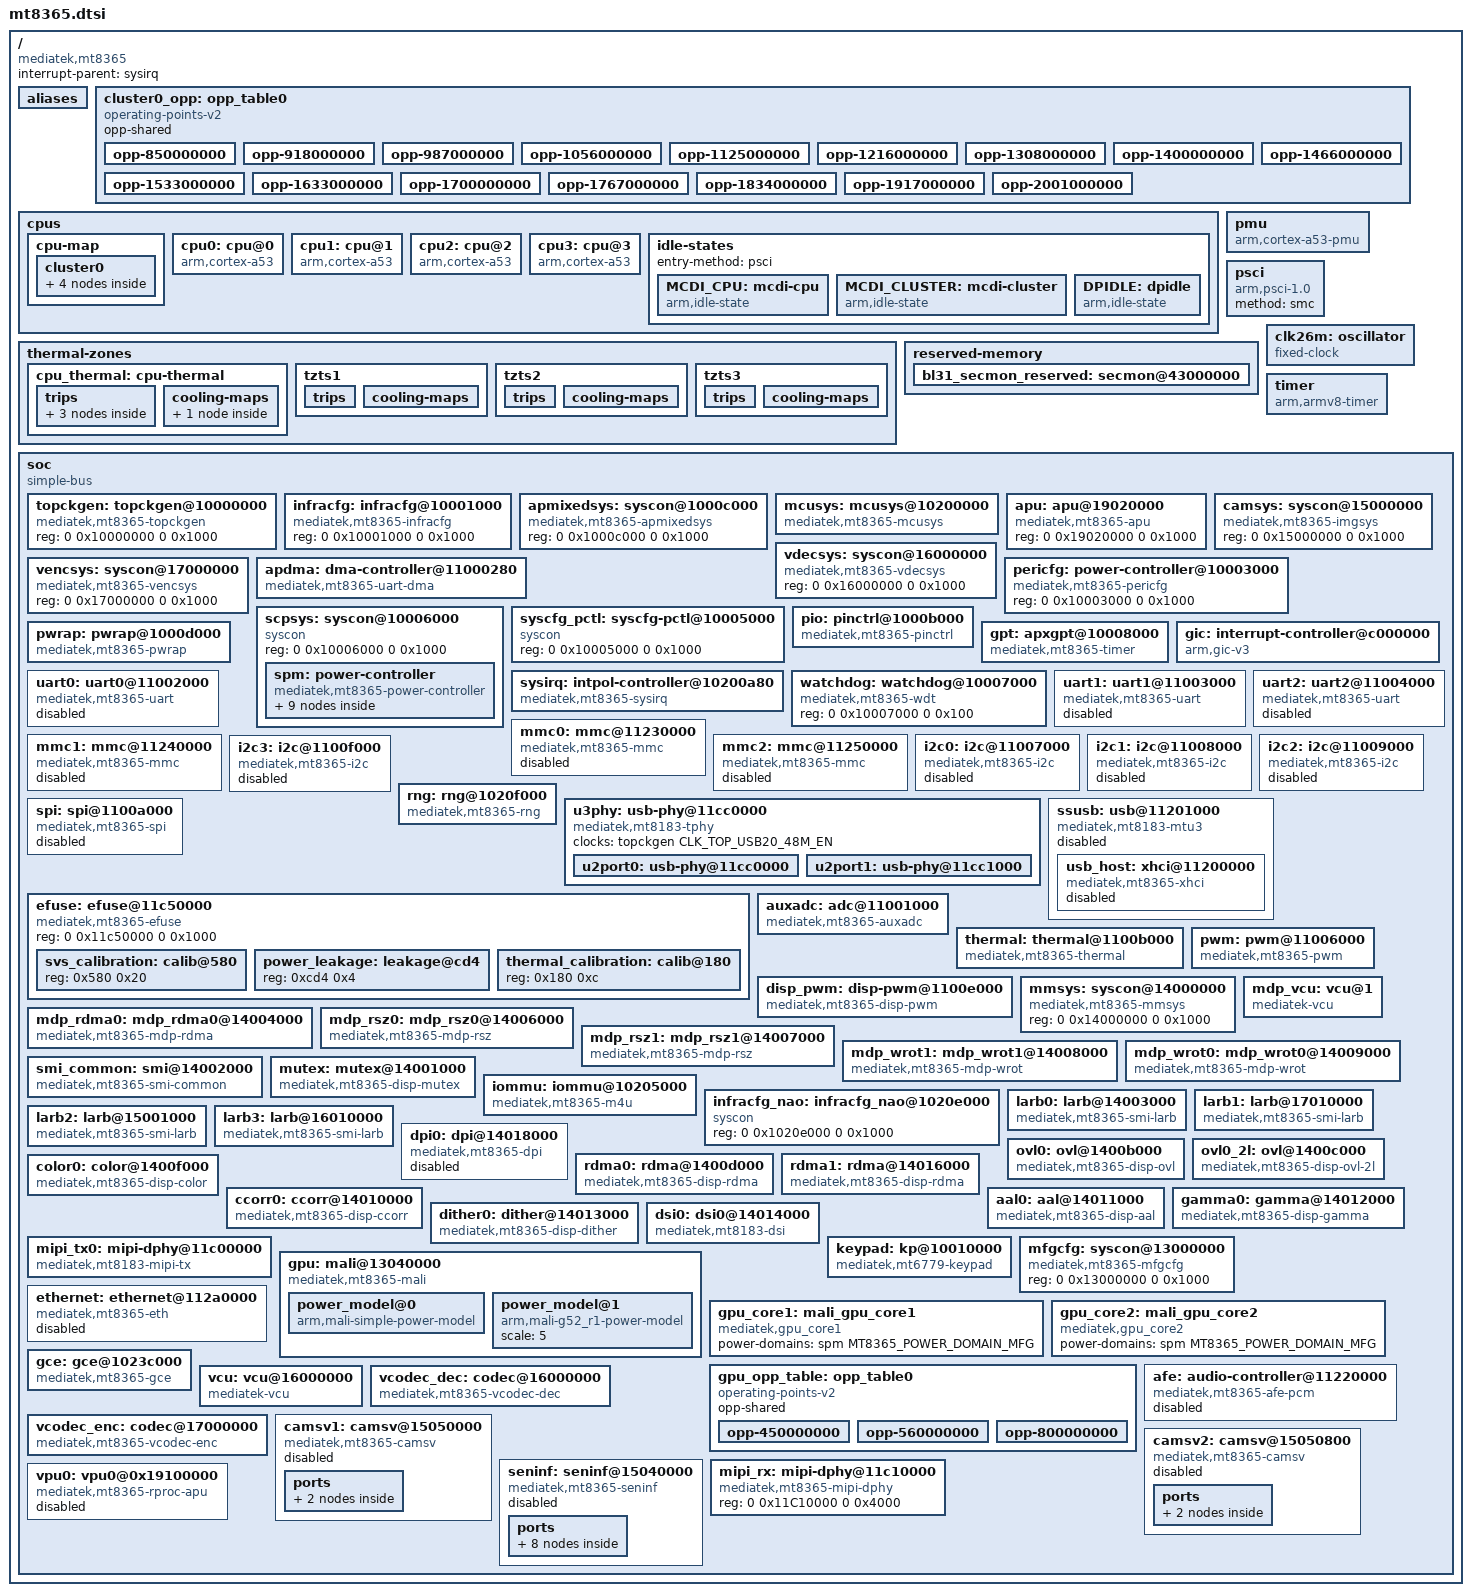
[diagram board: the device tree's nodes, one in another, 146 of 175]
// SPDX-License-Identifier: (GPL-2.0 OR MIT)
/*
 * Copyright (c) 2018 MediaTek Inc.
 */

#include <dt-bindings/clock/mt8365-clk.h>
#include <dt-bindings/interrupt-controller/arm-gic.h>
#include <dt-bindings/interrupt-controller/irq.h>
#include <dt-bindings/phy/phy.h>
#include <dt-bindings/gce/mt8365-gce.h>
#include <dt-bindings/power/mt8365-power.h>
#include <dt-bindings/memory/mt8365-larb-port.h>
#include <dt-bindings/thermal/thermal.h>

/ {
	compatible = "mediatek,mt8365";
	interrupt-parent = <&sysirq>;
	#address-cells = <2>;
	#size-cells = <2>;

	aliases {
		ovl0 = &ovl0;
		rdma0 = &rdma0;
		rdma1 = &rdma1;
		color0 = &color0;
		ccorr0 = &ccorr0;
		aal0 = &aal0;
		gamma0 = &gamma0;
		dither0 = &dither0;
		dsi0 = &dsi0;
		dpi0 = &dpi0;
	};

	cluster0_opp: opp_table0 {
		compatible = "operating-points-v2";
		opp-shared;
		opp-850000000 {
			opp-hz = /bits/ 64 <850000000>;
			opp-microvolt = <650000>;
		};
		opp-918000000 {
			opp-hz = /bits/ 64 <918000000>;
			opp-microvolt = <668750>;
		};
		opp-987000000 {
			opp-hz = /bits/ 64 <987000000>;
			opp-microvolt = <687500>;
		};
		opp-1056000000 {
			opp-hz = /bits/ 64 <1056000000>;
			opp-microvolt = <706250>;
		};
		opp-1125000000 {
			opp-hz = /bits/ 64 <1125000000>;
			opp-microvolt = <725000>;
		};
		opp-1216000000 {
			opp-hz = /bits/ 64 <1216000000>;
			opp-microvolt = <750000>;
		};
		opp-1308000000 {
			opp-hz = /bits/ 64 <1308000000>;
			opp-microvolt = <775000>;
		};
		opp-1400000000 {
			opp-hz = /bits/ 64 <1400000000>;
			opp-microvolt = <800000>;
		};
		opp-1466000000 {
			opp-hz = /bits/ 64 <1466000000>;
			opp-microvolt = <825000>;
		};
		opp-1533000000 {
			opp-hz = /bits/ 64 <1533000000>;
			opp-microvolt = <850000>;
		};
		opp-1633000000 {
			opp-hz = /bits/ 64 <1633000000>;
			opp-microvolt = <887500>;
		};
		opp-1700000000 {
			opp-hz = /bits/ 64 <1700000000>;
			opp-microvolt = <912500>;
		};
		opp-1767000000 {
			opp-hz = /bits/ 64 <1767000000>;
			opp-microvolt = <937500>;
		};
		opp-1834000000 {
			opp-hz = /bits/ 64 <1834000000>;
			opp-microvolt = <962500>;
		};
		opp-1917000000 {
			opp-hz = /bits/ 64 <1917000000>;
			opp-microvolt = <993750>;
		};
		opp-2001000000 {
			opp-hz = /bits/ 64 <2001000000>;
			opp-microvolt = <1025000>;
		};
	};

	cpus: cpus {
		#address-cells = <1>;
		#size-cells = <0>;

		cpu-map {
			cluster0: cluster0 {
				core0 {
					cpu = <&cpu0>;
				};
				core1 {
					cpu = <&cpu1>;
				};
				core2 {
					cpu = <&cpu2>;
				};
				core3 {
					cpu = <&cpu3>;
				};
			};
		};

		cpu0: cpu@0 {
			device_type = "cpu";
			compatible = "arm,cortex-a53";
			reg = <0x0>;
			clock-frequency = <1600000000>;
			clocks = <&mcusys CLK_MCU_BUS_SEL>,
				 <&apmixedsys CLK_APMIXED_MAINPLL>;
			clock-names = "cpu", "intermediate";
			cpu-idle-states = <&MCDI_CPU &MCDI_CLUSTER &DPIDLE>;
			operating-points-v2 = <&cluster0_opp>;
			#cooling-cells = <2>;
			enable-method = "psci";
		};

		cpu1: cpu@1 {
			device_type = "cpu";
			compatible = "arm,cortex-a53";
			reg = <0x1>;
			clock-frequency = <1600000000>;
			clocks = <&mcusys CLK_MCU_BUS_SEL>,
				 <&apmixedsys CLK_APMIXED_MAINPLL>;
			clock-names = "cpu", "intermediate", "armpll";
			cpu-idle-states = <&MCDI_CPU &MCDI_CLUSTER &DPIDLE>;
			operating-points-v2 = <&cluster0_opp>;
			#cooling-cells = <2>;
			enable-method = "psci";
		};

		cpu2: cpu@2 {
			device_type = "cpu";
			compatible = "arm,cortex-a53";
			reg = <0x2>;
			clock-frequency = <1600000000>;
			clocks = <&mcusys CLK_MCU_BUS_SEL>,
				 <&apmixedsys CLK_APMIXED_MAINPLL>;
			clock-names = "cpu", "intermediate", "armpll";
			cpu-idle-states = <&MCDI_CPU &MCDI_CLUSTER &DPIDLE>;
			operating-points-v2 = <&cluster0_opp>;
			#cooling-cells = <2>;
			enable-method = "psci";
		};

		cpu3: cpu@3 {
			device_type = "cpu";
			compatible = "arm,cortex-a53";
			reg = <0x3>;
			clock-frequency = <1600000000>;
			clocks = <&mcusys CLK_MCU_BUS_SEL>,
				 <&apmixedsys CLK_APMIXED_MAINPLL>;
			clock-names = "cpu", "intermediate", "armpll";
			cpu-idle-states = <&MCDI_CPU &MCDI_CLUSTER &DPIDLE>;
			operating-points-v2 = <&cluster0_opp>;
			#cooling-cells = <2>;
			enable-method = "psci";
		};

		idle-states {
			entry-method = "psci";

			MCDI_CPU: mcdi-cpu {
				compatible = "arm,idle-state";
				local-timer-stop;
				arm,psci-suspend-param = <0x00010001>;
				entry-latency-us = <300>;
				exit-latency-us = <200>;
				min-residency-us = <1000>;
			};

			MCDI_CLUSTER: mcdi-cluster {
				compatible = "arm,idle-state";
				local-timer-stop;
				arm,psci-suspend-param = <0x01010001>;
				entry-latency-us = <350>;
				exit-latency-us = <250>;
				min-residency-us = <1200>;
			};

			DPIDLE: dpidle {
				compatible = "arm,idle-state";
				local-timer-stop;
				arm,psci-suspend-param = <0x01010004>;
				entry-latency-us = <300>;
				exit-latency-us = <800>;
				min-residency-us = <3300>;
			};
		};
	};

	pmu {
		compatible = "arm,cortex-a53-pmu";
		interrupt-parent = <&gic>;
		interrupts = <GIC_PPI 7 IRQ_TYPE_LEVEL_LOW>;
	};

	thermal-zones {
		cpu_thermal: cpu-thermal {
			polling-delay-passive = <1000>; /* milliseconds */
			polling-delay = <1000>; /* milliseconds */
			thermal-sensors = <&thermal 0>;

			trips {
				threshold: trip-point0 {
					temperature = <95000>;
					hysteresis = <2000>;
					type = "passive";
				};

				target: trip-point1 {
					temperature = <105000>;
					hysteresis = <2000>;
					type = "passive";
				};

				cpu_crit: cpu_crit0 {
					temperature = <117000>;
					hysteresis = <2000>;
					type = "critical";
				};
			};

			cooling-maps {
				map0 {
					trip = <&target>;
					cooling-device =
						<&cpu0
						 THERMAL_NO_LIMIT
						 THERMAL_NO_LIMIT>,
						<&cpu1
						 THERMAL_NO_LIMIT
						 THERMAL_NO_LIMIT>,
						<&cpu2
						 THERMAL_NO_LIMIT
						 THERMAL_NO_LIMIT>,
						<&cpu3
						 THERMAL_NO_LIMIT
						 THERMAL_NO_LIMIT>;
					contribution = <100>;
				};
			};
		};

		tzts1: tzts1 {
			polling-delay-passive = <0>;
			polling-delay = <0>;
			thermal-sensors = <&thermal 1>;
			trips {};
			cooling-maps {};
		};

		tzts2: tzts2 {
			polling-delay-passive = <0>;
			polling-delay = <0>;
			thermal-sensors = <&thermal 2>;
			trips {};
			cooling-maps {};
		};

		tzts3: tzts3 {
			polling-delay-passive = <0>;
			polling-delay = <0>;
			thermal-sensors = <&thermal 3>;
			trips {};
			cooling-maps {};
		};
	};

	psci {
		compatible = "arm,psci-1.0";
		method = "smc";
	};

	reserved-memory {
		#address-cells = <2>;
		#size-cells = <2>;
		ranges;

		/* 192 KiB reserved for ARM Trusted Firmware (BL31) */
		bl31_secmon_reserved: secmon@43000000 {
			no-map;
			reg = <0 0x43000000 0 0x30000>;
		};
	};

	clk26m: oscillator {
		compatible = "fixed-clock";
		#clock-cells = <0>;
		clock-frequency = <26000000>;
		clock-output-names = "clk26m";
	};

	timer {
		compatible = "arm,armv8-timer";
		interrupt-parent = <&gic>;
		interrupts = <GIC_PPI 13 IRQ_TYPE_LEVEL_LOW 0>,
			     <GIC_PPI 14 IRQ_TYPE_LEVEL_LOW 0>,
			     <GIC_PPI 11 IRQ_TYPE_LEVEL_LOW 0>,
			     <GIC_PPI 10 IRQ_TYPE_LEVEL_LOW 0>;
	};

	soc {
		#address-cells = <2>;
		#size-cells = <2>;
		compatible = "simple-bus";
		ranges;

		topckgen: topckgen@10000000 {
			compatible = "mediatek,mt8365-topckgen", "syscon";
			reg = <0 0x10000000 0 0x1000>;
			#clock-cells = <1>;
		};

		infracfg: infracfg@10001000 {
			compatible = "mediatek,mt8365-infracfg", "syscon";
			reg = <0 0x10001000 0 0x1000>;
			#clock-cells = <1>;
		};

		apmixedsys: syscon@1000c000 {
			compatible = "mediatek,mt8365-apmixedsys", "syscon";
			reg = <0 0x1000c000 0 0x1000>;
			#clock-cells = <1>;
		};

		mcusys: mcusys@10200000 {
			compatible = "mediatek,mt8365-mcusys",
				     "mediatek,mt8365-mcucfg", "syscon";
			reg = <0 0x10200000 0 0x2000>;
			interrupts = <GIC_SPI 0 IRQ_TYPE_LEVEL_HIGH>;
			#clock-cells = <1>;
		};

		apu: apu@19020000 {
			compatible = "mediatek,mt8365-apu", "syscon";
			reg = <0 0x19020000 0 0x1000>;
			#clock-cells = <1>;
		};

		camsys: syscon@15000000 {
			compatible = "mediatek,mt8365-imgsys", "syscon";
			reg = <0 0x15000000 0 0x1000>;
			#clock-cells = <1>;
		};

		vdecsys: syscon@16000000 {
			compatible = "mediatek,mt8365-vdecsys", "syscon";
			reg = <0 0x16000000 0 0x1000>;
			#clock-cells = <1>;
		};

		vencsys: syscon@17000000 {
			compatible = "mediatek,mt8365-vencsys", "syscon";
			reg = <0 0x17000000 0 0x1000>;
			#clock-cells = <1>;
		};

		apdma: dma-controller@11000280 {
			compatible = "mediatek,mt8365-uart-dma",
				     "mediatek,mt6577-uart-dma";
			reg = <0 0x11000280 0 0x80>,
			      <0 0x11000300 0 0x80>,
			      <0 0x11000380 0 0x80>,
			      <0 0x11000400 0 0x80>,
			      <0 0x11000580 0 0x80>,
			      <0 0x11000600 0 0x80>;
			interrupts = <GIC_SPI 45 IRQ_TYPE_LEVEL_LOW>,
				     <GIC_SPI 46 IRQ_TYPE_LEVEL_LOW>,
				     <GIC_SPI 47 IRQ_TYPE_LEVEL_LOW>,
				     <GIC_SPI 48 IRQ_TYPE_LEVEL_LOW>,
				     <GIC_SPI 51 IRQ_TYPE_LEVEL_LOW>,
				     <GIC_SPI 52 IRQ_TYPE_LEVEL_LOW>;
			dma-requests = <6>;
			clocks = <&infracfg CLK_IFR_AP_DMA>;
			clock-names = "apdma";
			#dma-cells = <1>;
		};

		pericfg: power-controller@10003000 {
			compatible = "mediatek,mt8365-pericfg", "syscon";
			reg = <0 0x10003000 0 0x1000>;
			#clock-cells = <1>;
			#reset-cells = <1>;
		};

		scpsys: syscon@10006000 {
			compatible = "syscon", "simple-mfd";
			reg = <0 0x10006000 0 0x1000>;
			#power-domain-cells = <1>;

			/* System Power Manager */
			spm: power-controller {
				compatible = "mediatek,mt8365-power-controller";
				#address-cells = <1>;
				#size-cells = <0>;
				#power-domain-cells = <1>;

				/* power domains of the SoC */
				power-domain@MT8365_POWER_DOMAIN_MM {
					reg = <MT8365_POWER_DOMAIN_MM>;
					clocks = <&topckgen CLK_TOP_MM_SEL>,
						 <&mmsys CLK_MM_MM_SMI_COMMON>,
						 <&mmsys CLK_MM_MM_SMI_COMM0>,
						 <&mmsys CLK_MM_MM_SMI_COMM1>,
						 <&mmsys CLK_MM_MM_SMI_LARB0>;
					clock-names = "mm", "mm-0", "mm-1",
						      "mm-2", "mm-3";
					#power-domain-cells = <0>;
					mediatek,infracfg = <&infracfg>;
					mediatek,infracfg_nao = <&infracfg_nao>;
					#address-cells = <1>;
					#size-cells = <0>;

					power-domain@MT8365_POWER_DOMAIN_CAM {
						reg = <MT8365_POWER_DOMAIN_CAM>;
						clocks = <&camsys CLK_CAM_LARB2>,
							 <&camsys CLK_CAM_SENIF>,
							 <&camsys CLK_CAMSV0>,
							 <&camsys CLK_CAMSV1>,
							 <&camsys CLK_CAM_FDVT>,
							 <&camsys CLK_CAM_WPE>;
						clock-names = "cam-0", "cam-1",
							      "cam-2", "cam-3",
							      "cam-4", "cam-5";
						#power-domain-cells = <0>;
						mediatek,infracfg = <&infracfg>;
						mediatek,smi = <&smi_common>;
					};

					power-domain@MT8365_POWER_DOMAIN_VDEC {
						reg = <MT8365_POWER_DOMAIN_VDEC>;
						#power-domain-cells = <0>;
						mediatek,smi = <&smi_common>;
					};

					power-domain@MT8365_POWER_DOMAIN_VENC {
						reg = <MT8365_POWER_DOMAIN_VENC>;
						#power-domain-cells = <0>;
						mediatek,smi = <&smi_common>;
					};

					power-domain@MT8365_POWER_DOMAIN_APU {
						reg = <MT8365_POWER_DOMAIN_APU>;
						clocks = <&infracfg CLK_IFR_APU_AXI>,
							 <&apu CLK_APU_IPU_CK>,
							 <&apu CLK_APU_AXI>,
							 <&apu CLK_APU_JTAG>,
							 <&apu CLK_APU_IF_CK>,
							 <&apu CLK_APU_EDMA>,
							 <&apu CLK_APU_AHB>;
						clock-names = "apu", "apu-0",
							      "apu-1", "apu-2",
							      "apu-3", "apu-4",
							      "apu-5";
						#power-domain-cells = <0>;
						mediatek,infracfg = <&infracfg>;
						mediatek,smi = <&smi_common>;
					};
				};

				power-domain@MT8365_POWER_DOMAIN_CONN {
					reg = <MT8365_POWER_DOMAIN_CONN>;
					clocks = <&topckgen CLK_TOP_CONN_32K>,
						 <&topckgen CLK_TOP_CONN_26M>;
					clock-names = "conn", "conn1";
					#power-domain-cells = <0>;
					mediatek,infracfg = <&infracfg>;
				};

				power-domain@MT8365_POWER_DOMAIN_MFG {
					reg = <MT8365_POWER_DOMAIN_MFG>;
					clocks = <&topckgen CLK_TOP_MFG_SEL>;
					clock-names = "mfg";
					#power-domain-cells = <0>;
					mediatek,infracfg = <&infracfg>;
				};

				power-domain@MT8365_POWER_DOMAIN_AUDIO {
					reg = <MT8365_POWER_DOMAIN_AUDIO>;
					clocks = <&topckgen CLK_TOP_AUD_INTBUS_SEL>,
						 <&infracfg CLK_IFR_AUDIO>,
						 <&infracfg CLK_IFR_AUD_26M_BK>;
					clock-names = "audio", "audio1", "audio2";
					#power-domain-cells = <0>;
					mediatek,infracfg = <&infracfg>;
				};

				power-domain@MT8365_POWER_DOMAIN_DSP {
					reg = <MT8365_POWER_DOMAIN_DSP>;
					clocks = <&topckgen CLK_TOP_DSP_SEL>,
						 <&topckgen CLK_TOP_DSP_26M>;
					clock-names = "dsp", "dsp1";
					#power-domain-cells = <0>;
					mediatek,infracfg = <&infracfg>;
				};
			};
		};

		syscfg_pctl: syscfg-pctl@10005000 {
			compatible = "syscon";
			reg = <0 0x10005000 0 0x1000>;
		};

		pio: pinctrl@1000b000 {
			compatible = "mediatek,mt8365-pinctrl";
			reg = <0 0x1000b000 0 0x1000>;
			mediatek,pctl-regmap = <&syscfg_pctl>;
			pins-are-numbered;
			gpio-controller;
			#gpio-cells = <2>;
			interrupt-controller;
			#interrupt-cells = <2>;
			interrupts = <GIC_SPI 115 IRQ_TYPE_LEVEL_HIGH>;
		};

		pwrap: pwrap@1000d000 {
			compatible = "mediatek,mt8365-pwrap";
			reg = <0 0x1000d000 0 0x1000>;
			reg-names = "pwrap";
			interrupts = <GIC_SPI 123 IRQ_TYPE_LEVEL_HIGH>;
			clocks = <&infracfg CLK_IFR_PWRAP_SPI>,
				 <&infracfg CLK_IFR_PMIC_AP>,
				 <&infracfg CLK_IFR_PWRAP_SYS>,
				 <&infracfg CLK_IFR_PWRAP_TMR>;
			clock-names = "spi", "wrap", "wrap_sys", "wrap_tmr";
		};

		gpt: apxgpt@10008000 {
			compatible = "mediatek,mt8365-timer",
				     "mediatek,mt6577-timer";
			reg = <0 0x10008000 0 0x1000>;
			interrupts = <GIC_SPI 114 IRQ_TYPE_LEVEL_LOW>;
			clocks = <&topckgen CLK_TOP_SYS_26M_D2>;
			clock-names = "clk13m";
		};

		gic: interrupt-controller@c000000 {
			compatible = "arm,gic-v3";
			#interrupt-cells = <3>;
			interrupt-parent = <&gic>;
			interrupt-controller;
			reg = <0 0xc000000 0 0x80000>,
			      <0 0xc080000 0 0x80000>;

			interrupts = <GIC_PPI 9
				(GIC_CPU_MASK_SIMPLE(4) | IRQ_TYPE_LEVEL_HIGH)>;
		};

		sysirq: intpol-controller@10200a80 {
			compatible = "mediatek,mt8365-sysirq",
				     "mediatek,mt6577-sysirq";
			interrupt-controller;
			#interrupt-cells = <3>;
			interrupt-parent = <&gic>;
			reg = <0 0x10200a80 0 0x20>;
		};

		watchdog: watchdog@10007000 {
			compatible = "mediatek,mt8365-wdt",
				     "mediatek,mt6589-wdt";
			reg = <0 0x10007000 0 0x100>;
			#reset-cells = <1>;
		};

		uart0: uart0@11002000 {
			compatible = "mediatek,mt8365-uart",
				     "mediatek,mt6577-uart";
			reg = <0 0x11002000 0 0x1000>;
			interrupts = <GIC_SPI 35 IRQ_TYPE_LEVEL_LOW>;
			clocks = <&clk26m>, <&infracfg CLK_IFR_UART0>;
			clock-names = "baud", "bus";
			dmas = <&apdma 0
				&apdma 1>;
			dma-names = "tx", "rx";
			status = "disabled";
		};

		uart1: uart1@11003000 {
			compatible = "mediatek,mt8365-uart",
				     "mediatek,mt6577-uart";
			reg = <0 0x11003000 0 0x1000>;
			interrupts = <GIC_SPI 36 IRQ_TYPE_LEVEL_LOW>;
			clocks = <&clk26m>, <&infracfg CLK_IFR_UART1>;
			clock-names = "baud", "bus";
			dmas = <&apdma 2
				&apdma 3>;
			dma-names = "tx", "rx";
			status = "disabled";
		};

		uart2: uart2@11004000 {
			compatible = "mediatek,mt8365-uart",
				     "mediatek,mt6577-uart";
			reg = <0 0x11004000 0 0x1000>;
			interrupts = <GIC_SPI 37 IRQ_TYPE_LEVEL_LOW>;
			clocks = <&clk26m>, <&infracfg CLK_IFR_UART2>;
			clock-names = "baud", "bus";
			dmas = <&apdma 4
				&apdma 5>;
			dma-names = "tx", "rx";
			status = "disabled";
		};

		mmc0: mmc@11230000 {
			compatible = "mediatek,mt8365-mmc",
				     "mediatek,mt8183-mmc";
			reg = <0 0x11230000 0 0x1000>,
			      <0 0x11cd0000 0 0x1000>;
			interrupts = <GIC_SPI 23 IRQ_TYPE_LEVEL_LOW>;
			clocks = <&topckgen CLK_TOP_MSDC50_0_SEL>,
				 <&infracfg CLK_IFR_MSDC0_HCLK>,
				 <&infracfg CLK_IFR_MSDC0_SRC>;
			clock-names = "source", "hclk", "source_cg";
			status = "disabled";
		};

		mmc1: mmc@11240000 {
			compatible = "mediatek,mt8365-mmc",
				     "mediatek,mt8183-mmc";
			reg = <0 0x11240000 0 0x1000>,
			      <0 0x11c90000 0 0x1000>;
			interrupts = <GIC_SPI 24 IRQ_TYPE_LEVEL_LOW>;
			clocks = <&topckgen CLK_TOP_MSDC30_1_SEL>,
				 <&infracfg CLK_IFR_MSDC1_HCLK>,
				 <&infracfg CLK_IFR_MSDC1_SRC>;
			clock-names = "source", "hclk", "source_cg";
			status = "disabled";
		};

		mmc2: mmc@11250000 {
			compatible = "mediatek,mt8365-mmc",
				     "mediatek,mt8183-mmc";
			reg = <0 0x11250000 0 0x1000>,
			      <0 0x11c60000 0 0x1000>;
			interrupts = <GIC_SPI 68 IRQ_TYPE_LEVEL_LOW>;
			clocks = <&topckgen CLK_TOP_MSDC50_2_SEL>,
				 <&infracfg CLK_IFR_MSDC2_HCLK>,
				 <&infracfg CLK_IFR_MSDC2_SRC>,
				 <&infracfg CLK_IFR_MSDC2_BK>,
				 <&infracfg CLK_IFR_AP_MSDC0>;
			clock-names = "source", "hclk", "source_cg",
				      "bus_clk", "sys_cg";
			mediatek,disable-single-burst;
			status = "disabled";
		};

		i2c0: i2c@11007000 {
			compatible = "mediatek,mt8365-i2c";
			reg = <0 0x11007000 0 0xa0>,
			      <0 0x11000080 0 0x80>;
			interrupts = <GIC_SPI 28 IRQ_TYPE_LEVEL_LOW>;
			clock-div = <1>;
			clocks = <&infracfg CLK_IFR_I2C0_AXI>,
				 <&infracfg CLK_IFR_AP_DMA>;
			clock-names = "main", "dma";
			#address-cells = <1>;
			#size-cells = <0>;
			status = "disabled";
		};

		i2c1: i2c@11008000 {
			compatible = "mediatek,mt8365-i2c";
			reg = <0 0x11008000 0 0xa0>,
			      <0 0x11000100 0 0x80>;
			interrupts = <GIC_SPI 29 IRQ_TYPE_LEVEL_LOW>;
			clock-div = <1>;
			clocks = <&infracfg CLK_IFR_I2C1_AXI>,
				 <&infracfg CLK_IFR_AP_DMA>;
			clock-names = "main", "dma";
			#address-cells = <1>;
			#size-cells = <0>;
			status = "disabled";
		};

		i2c2: i2c@11009000 {
			compatible = "mediatek,mt8365-i2c";
			reg = <0 0x11009000 0 0xa0>,
			      <0 0x11000180 0 0x80>;
			interrupts = <GIC_SPI 30 IRQ_TYPE_LEVEL_LOW>;
			clock-div = <1>;
			clocks = <&infracfg CLK_IFR_I2C2_AXI>,
				 <&infracfg CLK_IFR_AP_DMA>;
			clock-names = "main", "dma";
			#address-cells = <1>;
			#size-cells = <0>;
			status = "disabled";
		};

		i2c3: i2c@1100f000 {
			compatible = "mediatek,mt8365-i2c";
			reg = <0 0x1100f000 0 0xa0>,
			      <0 0x11000200 0 0x80>;
			interrupts = <GIC_SPI 31 IRQ_TYPE_LEVEL_LOW>;
			clock-div = <1>;
			clocks = <&infracfg CLK_IFR_I2C3_AXI>,
				 <&infracfg CLK_IFR_AP_DMA>;
			clock-names = "main", "dma";
			#address-cells = <1>;
			#size-cells = <0>;
			status = "disabled";
		};

		rng: rng@1020f000 {
			compatible = "mediatek,mt8365-rng",
				     "mediatek,mt7623-rng";
			reg = <0 0x1020f000 0 0x100>;
			clocks = <&infracfg CLK_IFR_TRNG>;
			clock-names = "rng";
		};

		u3phy: usb-phy@11cc0000 {
			compatible = "mediatek,mt8183-tphy",
				     "mediatek,generic-tphy-v2";
			clocks = <&topckgen CLK_TOP_USB20_48M_EN>;
			clock-names = "u3phya_ref";
			#address-cells = <2>;
			#phy-cells = <1>;
			#size-cells = <2>;
			ranges;
			status = "okay";

			u2port0: usb-phy@11cc0000 {
				reg = <0 0x11cc0000 0 0x400>;
				clocks = <&topckgen CLK_TOP_SSUSB_PHY_CK_EN>,
					 <&topckgen CLK_TOP_USB20_48M_EN>;
				clock-names = "ref", "da_ref";
				#phy-cells = <1>;
				status = "okay";
			};

			u2port1: usb-phy@11cc1000 {
				reg = <0 0x11cc1000 0 0x400>;
				clocks = <&topckgen CLK_TOP_SSUSB_PHY_CK_EN>,
					 <&topckgen CLK_TOP_USB20_48M_EN>;
				clock-names = "ref", "da_ref";
				#phy-cells = <1>;
				status = "okay";
			};
		};

		ssusb: usb@11201000 {
			compatible ="mediatek,mt8183-mtu3", "mediatek,mtu3";
			reg = <0 0x11201000 0 0x2e00>,
			      <0 0x11203e00 0 0x0100>;
			reg-names = "mac", "ippc";
			interrupts = <GIC_SPI 16 IRQ_TYPE_LEVEL_LOW>;
			phys = <&u2port0 PHY_TYPE_USB2>,
			       <&u2port1 PHY_TYPE_USB2>;
			clocks = <&topckgen CLK_TOP_SSUSB_TOP_CK_EN>,
				 <&infracfg CLK_IFR_SSUSB_REF>,
				 <&infracfg CLK_IFR_SSUSB_SYS>,
				 <&infracfg CLK_IFR_ICUSB>;
			clock-names = "sys_ck", "ref_ck", "mcu_ck",
				      "dma_ck";
			#address-cells = <2>;
			#size-cells = <2>;
			ranges;
			status = "disabled";
			wakeup-source;
			mediatek,syscon-wakeup = <&pericfg 0x400 0>;

			usb_host: xhci@11200000 {
				compatible = "mediatek,mt8365-xhci",
					     "mediatek,mtk-xhci";
				reg = <0 0x11200000 0 0x1000>;
				reg-names = "mac";
				interrupts = <GIC_SPI 67 IRQ_TYPE_LEVEL_LOW>;
				clocks = <&topckgen CLK_TOP_SSUSB_TOP_CK_EN>,
					 <&infracfg CLK_IFR_SSUSB_REF>,
					 <&infracfg CLK_IFR_SSUSB_SYS>,
					 <&infracfg CLK_IFR_ICUSB>,
					 <&infracfg CLK_IFR_SSUSB_XHCI>;
				clock-names = "sys_ck", "ref_ck", "mcu_ck",
					      "dma_ck", "xhci_ck";
				status = "disabled";
			};
		};

		spi: spi@1100a000 {
			compatible = "mediatek,mt8365-spi",
				     "mediatek,mt7622-spi";
			#address-cells = <1>;
			#size-cells = <0>;
			reg = <0 0x1100a000 0 0x100>;
			interrupts = <GIC_SPI 62 IRQ_TYPE_LEVEL_LOW>;
			clocks = <&topckgen CLK_TOP_UNIVPLL2_D4>,
				 <&topckgen CLK_TOP_SPI_SEL>,
				 <&infracfg CLK_IFR_SPI0>;
			clock-names = "parent-clk", "sel-clk", "spi-clk";
			status = "disabled";
		};

		efuse: efuse@11c50000 {
			compatible = "mediatek,mt8365-efuse", "mediatek,efuse";
			reg = <0 0x11c50000 0 0x1000>;
			#address-cells = <1>;
			#size-cells = <1>;

			svs_calibration: calib@580 {
				reg = <0x580 0x20>;
			};

			power_leakage: leakage@cd4 {
				reg = <0xcd4 0x4>;
			};

			thermal_calibration: calib@180 {
				reg = <0x180 0xc>;
			};
		};

		auxadc: adc@11001000 {
			compatible = "mediatek,mt8365-auxadc",
				     "mediatek,mt8173-auxadc";
			reg = <0 0x11001000 0 0x1000>;
			clocks = <&infracfg CLK_IFR_AUXADC>;
			clock-names = "main";
			#io-channel-cells = <1>;
		};

		thermal: thermal@1100b000 {
			compatible = "mediatek,mt8365-thermal";
			reg = <0 0x1100b000 0 0x1000>;
			interrupts = <GIC_SPI 22 IRQ_TYPE_LEVEL_LOW>;
			clocks = <&infracfg CLK_IFR_THERM>,
				 <&infracfg CLK_IFR_AUXADC>;
			clock-names = "therm", "auxadc";
			mediatek,auxadc = <&auxadc>;
			mediatek,apmixedsys = <&apmixedsys>;
			nvmem-cells = <&thermal_calibration>;
			nvmem-cell-names = "calibration-data";
			#thermal-sensor-cells = <1>;
		};

		pwm: pwm@11006000 {
			compatible = "mediatek,mt8365-pwm";
			reg = <0 0x11006000 0 0x1000>;
			#pwm-cells = <2>;
			interrupts = <GIC_SPI 76 IRQ_TYPE_LEVEL_LOW>;
			clocks = <&infracfg CLK_IFR_PWM_HCLK>,
				 <&infracfg CLK_IFR_PWM>,
				 <&infracfg CLK_IFR_PWM1>,
				 <&infracfg CLK_IFR_PWM2>,
				 <&infracfg CLK_IFR_PWM3>;
			clock-names = "top", "main", "pwm1", "pwm2", "pwm3";
		};

		disp_pwm: disp-pwm@1100e000 {
			compatible = "mediatek,mt8365-disp-pwm",
				     "mediatek,mt8183-disp-pwm";
			reg = <0 0x1100e000 0 0x1000>;
			#pwm-cells = <2>;
			clocks = <&topckgen CLK_TOP_DISP_PWM_SEL>,
				 <&infracfg CLK_IFR_DISP_PWM>;
			clock-names = "main", "mm";
			power-domains = <&spm MT8365_POWER_DOMAIN_MM>;
		};

		mmsys: syscon@14000000 {
			compatible = "mediatek,mt8365-mmsys", "syscon";
			reg = <0 0x14000000 0 0x1000>;
			#clock-cells = <1>;
		};

		mdp_vcu: vcu@1 {
			compatible = "mediatek-vcu",
				     "mediatek,mt8167-vcu";
			mediatek,vcuid = <1>;
			mediatek,vcuname = "vcu1";
			iommus = <&iommu M4U_PORT_HW_VDEC_MC_EXT>;
		};

		mdp_rdma0: mdp_rdma0@14004000 {
			compatible = "mediatek,mt8365-mdp-rdma",
						"mediatek,mt8167-mdp-rdma",
						"mediatek,mt8167-mdp";
			reg = <0 0x14004000 0 0x1000>;
			mediatek,mdp-id = <0>;
			clocks = <&mmsys CLK_MM_MM_MDP_RDMA0>,
				 <&mmsys CLK_MM_MM_MDP_RDMA0>;
			power-domains = <&spm MT8365_POWER_DOMAIN_MM>;
			iommus = <&iommu M4U_PORT_MDP_RDMA0>;
			mediatek,larb = <&larb0>;
			mediatek,vpu = <&mdp_vcu>;
			mediatek,gce = <&gce>;
			mboxes = <&gce 8 2 1>;
		};

		mdp_rsz0: mdp_rsz0@14006000 {
			compatible = "mediatek,mt8365-mdp-rsz",
						"mediatek,mt8167-mdp-rsz";
			mediatek,mdp-id = <0>;
			reg = <0 0x14006000 0 0x1000>;
			mediatek,gce-client-reg = <&gce SUBSYS_1400XXXX 0x6000 0x1000>;
			clocks = <&mmsys CLK_MM_MM_MDP_RSZ0>;
		};

		mdp_rsz1: mdp_rsz1@14007000 {
			compatible = "mediatek,mt8365-mdp-rsz",
						"mediatek,mt8167-mdp-rsz";
			mediatek,mdp-id = <1>;
			reg = <0 0x14007000 0 0x1000>;
			mediatek,gce-client-reg = <&gce SUBSYS_1400XXXX 0x7000 0x1000>;
			clocks = <&mmsys CLK_MM_MM_MDP_RSZ1>;
		};

		mdp_wrot1: mdp_wrot1@14008000 {
			compatible = "mediatek,mt8365-mdp-wrot",
						"mediatek,mt8167-mdp-wrot";
			mediatek,mdp-id = <0>;
			reg = <0 0x14008000 0 0x1000>;
			power-domains = <&spm MT8365_POWER_DOMAIN_MM>;
			mediatek,gce-client-reg = <&gce SUBSYS_1400XXXX 0x8000 0x1000>;
			clocks = <&mmsys CLK_MM_MM_MDP_WDMA0>;
			iommus = <&iommu M4U_PORT_MDP_WROT1>;
			mediatek,larb = <&larb0>;
		};

		mdp_wrot0: mdp_wrot0@14009000 {
			compatible = "mediatek,mt8365-mdp-wrot",
						"mediatek,mt8167-mdp-wrot";
			mediatek,mdp-id = <0>;
			reg = <0 0x14009000 0 0x1000>;
			power-domains = <&spm MT8365_POWER_DOMAIN_MM>;
			mediatek,gce-client-reg = <&gce SUBSYS_1400XXXX 0x9000 0x1000>;
			clocks = <&mmsys CLK_MM_MM_MDP_WROT0>;
			iommus = <&iommu M4U_PORT_MDP_WROT0>;
			mediatek,larb = <&larb0>;
		};

		smi_common: smi@14002000 {
			compatible = "mediatek,mt8365-smi-common", "syscon";
			reg = <0 0x14002000 0 0x1000>;
			clocks = <&mmsys CLK_MM_MM_SMI_COMMON>,
				 <&mmsys CLK_MM_MM_SMI_COMMON>,
				 <&mmsys CLK_MM_MM_SMI_COMM0>,
				 <&mmsys CLK_MM_MM_SMI_COMM1>;
			clock-names = "apb", "smi", "gals0", "gals1";
			mediatek,mmsys = <&mmsys>;
		};

		mutex: mutex@14001000 {
			compatible =  "mediatek,mt8365-disp-mutex";
			reg = <0 0x14001000 0 0x1000>;
			interrupts = <GIC_SPI 154 IRQ_TYPE_LEVEL_LOW>;
			power-domains = <&spm MT8365_POWER_DOMAIN_MM>;
		};

		iommu: iommu@10205000 {
			compatible = "mediatek,mt8365-m4u";
			reg = <0 0x10205000 0 0x1000>;
			interrupts = <GIC_SPI 102 IRQ_TYPE_LEVEL_LOW>;
			mediatek,larbs = <&larb0 &larb1 &larb2 &larb3>;
			#iommu-cells = <1>;
		};

		infracfg_nao: infracfg_nao@1020e000 {
			compatible = "syscon";
			reg = <0 0x1020e000 0 0x1000>;
		};

		larb0: larb@14003000 {
			compatible = "mediatek,mt8365-smi-larb",
				     "mediatek,mt8183-smi-larb";
			reg = <0 0x14003000 0 0x1000>;
			mediatek,smi = <&smi_common>;
			clocks = <&mmsys CLK_MM_MM_SMI_LARB0>,
				 <&mmsys CLK_MM_MM_SMI_LARB0>;
			clock-names = "apb", "smi";
			power-domains = <&spm MT8365_POWER_DOMAIN_MM>;
		};

		larb1: larb@17010000 {
			compatible = "mediatek,mt8365-smi-larb",
				     "mediatek,mt8183-smi-larb";
			reg = <0 0x17010000 0 0x1000>;
			mediatek,smi = <&smi_common>;
			clocks = <&vencsys CLK_VENC>, <&vencsys CLK_VENC>;
			clock-names = "apb", "smi";
			power-domains = <&spm MT8365_POWER_DOMAIN_VENC>;
		};

		larb2: larb@15001000 {
			compatible = "mediatek,mt8365-smi-larb",
				     "mediatek,mt8183-smi-larb";
			reg = <0 0x15001000 0 0x1000>;
			mediatek,smi = <&smi_common>;
			clocks = <&mmsys CLK_MM_MM_SMI_IMG>,
				 <&camsys CLK_CAM_LARB2>;
			clock-names = "apb", "smi";
			power-domains = <&spm MT8365_POWER_DOMAIN_CAM>;
		};

		larb3: larb@16010000 {
			compatible = "mediatek,mt8365-smi-larb",
				     "mediatek,mt8183-smi-larb";
			reg = <0 0x16010000 0 0x1000>;
			mediatek,smi = <&smi_common>;
			clocks = <&vdecsys CLK_VDEC_LARB1>,
				 <&vdecsys CLK_VDEC_LARB1>;
			clock-names = "apb", "smi";
			power-domains = <&spm MT8365_POWER_DOMAIN_VDEC>;
		};

		dpi0: dpi@14018000 {
			compatible = "mediatek,mt8365-dpi";
			reg = <0 0x14018000 0 0x1000>;
			interrupts = <GIC_SPI 197 IRQ_TYPE_LEVEL_LOW>;
			power-domains = <&spm MT8365_POWER_DOMAIN_MM>;
			clocks = <&mmsys CLK_MM_DPI0_DPI0>,
				 <&mmsys CLK_MM_MM_DPI0>,
				 <&apmixedsys CLK_APMIXED_LVDSPLL>,
				 <&topckgen CLK_TOP_DPI0_SEL>;
			clock-names = "dpi_sel", "engine", "pll", "pixel";
			assigned-clocks = <&topckgen CLK_TOP_DPI0_SEL>;
			assigned-clock-parents = <&topckgen CLK_TOP_LVDSPLL_D4>;
			status = "disabled";
		};

		ovl0: ovl@1400b000 {
			compatible = "mediatek,mt8365-disp-ovl",
				     "mediatek,mt8183-disp-ovl";
			reg = <0 0x1400b000 0 0x1000>;
			interrupts = <GIC_SPI 161 IRQ_TYPE_LEVEL_LOW>;
			power-domains = <&spm MT8365_POWER_DOMAIN_MM>;
			clocks = <&mmsys CLK_MM_MM_DISP_OVL0>;
			iommus = <&iommu M4U_PORT_DISP_OVL0>;
			mediatek,larb = <&larb0>;
		};

		ovl0_2l: ovl@1400c000 {
			compatible = "mediatek,mt8365-disp-ovl-2l",
				     "mediatek,mt8183-disp-ovl-2l";
			reg = <0 0x1400c000 0 0x1000>;
			interrupts = <GIC_SPI 173 IRQ_TYPE_LEVEL_LOW>;
			power-domains = <&spm MT8365_POWER_DOMAIN_MM>;
			clocks = <&mmsys CLK_MM_MM_DISP_OVL0_2L>;
			iommus = <&iommu M4U_PORT_DISP_OVL0_2L>;
			mediatek,larb = <&larb0>;
		};

		rdma0: rdma@1400d000 {
			compatible = "mediatek,mt8365-disp-rdma",
				     "mediatek,mt8183-disp-rdma";
			reg = <0 0x1400d000 0 0x1000>;
			interrupts = <GIC_SPI 162 IRQ_TYPE_LEVEL_LOW>;
			power-domains = <&spm MT8365_POWER_DOMAIN_MM>;
			clocks = <&mmsys CLK_MM_MM_DISP_RDMA0>;
			iommus = <&iommu M4U_PORT_DISP_RDMA0>;
			mediatek,larb = <&larb0>;
		};

		rdma1: rdma@14016000 {
			compatible = "mediatek,mt8365-disp-rdma",
				     "mediatek,mt8183-disp-rdma";
			reg = <0 0x14016000 0 0x1000>;
			interrupts = <GIC_SPI 195 IRQ_TYPE_LEVEL_LOW>;
			power-domains = <&spm MT8365_POWER_DOMAIN_MM>;
			clocks = <&mmsys CLK_MM_MM_DISP_RDMA1>;
			iommus = <&iommu M4U_PORT_DISP_RDMA1>;
			mediatek,rdma-fifo-size = <2048>;
			mediatek,larb = <&larb0>;
		};

		color0: color@1400f000 {
			compatible = "mediatek,mt8365-disp-color",
				     "mediatek,mt8173-disp-color";
			reg = <0 0x1400f000 0 0x1000>;
			interrupts = <GIC_SPI 164 IRQ_TYPE_LEVEL_LOW>;
			power-domains = <&spm MT8365_POWER_DOMAIN_MM>;
			clocks = <&mmsys CLK_MM_MM_DISP_COLOR0>;
		};

		ccorr0: ccorr@14010000 {
			compatible = "mediatek,mt8365-disp-ccorr",
				     "mediatek,mt8183-disp-ccorr";
			reg = <0 0x14010000 0 0x1000>;
			interrupts = <GIC_SPI 165 IRQ_TYPE_LEVEL_LOW>;
			power-domains = <&spm MT8365_POWER_DOMAIN_MM>;
			clocks = <&mmsys CLK_MM_MM_DISP_CCORR0>;
		};

		aal0: aal@14011000 {
			compatible = "mediatek,mt8365-disp-aal",
				     "mediatek,mt8183-disp-aal";
			reg = <0 0x14011000 0 0x1000>;
			interrupts = <GIC_SPI 166 IRQ_TYPE_LEVEL_LOW>;
			power-domains = <&spm MT8365_POWER_DOMAIN_MM>;
			clocks = <&mmsys CLK_MM_MM_DISP_AAL0>;
		};

		gamma0: gamma@14012000 {
			compatible = "mediatek,mt8365-disp-gamma",
				     "mediatek,mt8183-disp-gamma";
			reg = <0 0x14012000 0 0x1000>;
			interrupts = <GIC_SPI 167 IRQ_TYPE_LEVEL_LOW>;
			power-domains = <&spm MT8365_POWER_DOMAIN_MM>;
			clocks = <&mmsys CLK_MM_MM_DISP_GAMMA0>;
		};

		dither0: dither@14013000 {
			compatible = "mediatek,mt8365-disp-dither";
			reg = <0 0x14013000 0 0x1000>;
			interrupts = <GIC_SPI 168 IRQ_TYPE_LEVEL_LOW>;
			power-domains = <&spm MT8365_POWER_DOMAIN_MM>;
			clocks = <&mmsys CLK_MM_MM_DISP_DITHER0>;
		};

		dsi0: dsi0@14014000 {
			compatible = "mediatek,mt8183-dsi";
			reg = <0 0x14014000 0 0x1000>;
			interrupts = <GIC_SPI 169 IRQ_TYPE_LEVEL_LOW>;
			power-domains = <&spm MT8365_POWER_DOMAIN_MM>;
			clocks = <&mmsys CLK_MM_MM_DSI0>,
				 <&mmsys CLK_MM_DSI0_DIG_DSI>,
				 <&mipi_tx0>;
			clock-names = "engine", "digital", "hs";
			phys = <&mipi_tx0>;
			phy-names = "dphy";
		};

		mipi_tx0: mipi-dphy@11c00000 {
			compatible = "mediatek,mt8183-mipi-tx";
			reg = <0 0x11c00000 0 0x800>;
			clocks = <&clk26m>;
			clock-names = "ref_clk";
			#clock-cells = <0>;
			#phy-cells = <0>;
			clock-output-names = "mipi_tx0_pll";
		};

		keypad: kp@10010000 {
			compatible = "mediatek,mt6779-keypad";
			reg = <0 0x10010000 0 0x1000>;
			wakeup-source;
			interrupts = <GIC_SPI 124 IRQ_TYPE_EDGE_FALLING>;
			clocks = <&clk26m>;
			clock-names = "kpd";
		};

		mfgcfg: syscon@13000000 {
			compatible = "mediatek,mt8365-mfgcfg", "syscon";
			reg = <0 0x13000000 0 0x1000>;
			#clock-cells = <1>;
		};

		gpu: mali@13040000 {
			compatible = "mediatek,mt8365-mali", "arm,mali-bifrost", "arm,mali-midgard";
			reg = <0 0x13040000 0 0x4000>;
			interrupts =
				<GIC_SPI 201 IRQ_TYPE_LEVEL_LOW>,
				<GIC_SPI 202 IRQ_TYPE_LEVEL_LOW>,
				<GIC_SPI 203 IRQ_TYPE_LEVEL_LOW>,
				<GIC_SPI 204 IRQ_TYPE_LEVEL_LOW>;
			interrupt-names =
				"GPU",
				"MMU",
				"JOB",
				"EVENT";

			/*
			 * Note: the properties below are not part of the
			 * upstream binding.
			 */
			clocks =
				<&topckgen CLK_TOP_MFGPLL>,
				<&topckgen CLK_TOP_MFG_SEL>,
				<&topckgen CLK_TOP_UNIVPLL_D3>,
				<&mfgcfg CLK_MFG_BG3D>;
			clock-names =
				"clk_main_parent",
				"clk_mux",
				"clk_sub_parent",
				"subsys_mfg_cg";

			power-domains = <&spm MT8365_POWER_DOMAIN_MFG>;

			#cooling-cells = <2>;
			cooling-min-level = <0>;
			cooling-max-level = <15>;

			operating-points-v2 = <&gpu_opp_table>;

			power_model@0 {
				compatible = "arm,mali-simple-power-model";
				static-coefficient = <2427750>;
				dynamic-coefficient = <4687>;
				ts = <20000 2000 (-20) 2>;
				//thermal-zone = "cpu_thermal"; /* Note: Enable it when cpu_thermal device can be successfully probed*/
			};
			power_model@1 {
				compatible = "arm,mali-g52_r1-power-model";
				scale = <5>;
			};
		};

		gpu_core1: mali_gpu_core1 {
			compatible = "mediatek,gpu_core1";
			power-domains = <&spm MT8365_POWER_DOMAIN_MFG>;
		};

		gpu_core2: mali_gpu_core2 {
			compatible = "mediatek,gpu_core2";
			power-domains = <&spm MT8365_POWER_DOMAIN_MFG>;
		};

		gpu_opp_table: opp_table0 {
			/*
			 * Note: "operating-points-v2-mali" compatible and the
			 * opp-core-mask properties are not part of upstream
			 * binding.
			 */

			compatible = "operating-points-v2", "operating-points-v2-mali";
			opp-shared;

			opp-450000000 {
				opp-hz = /bits/ 64 <450000000>;
				opp-hz-real = /bits/ 64 <450000000>,
					      /bits/ 64 <450000000>;
				opp-microvolt = <650000>;
			};
			opp-560000000 {
				opp-hz = /bits/ 64 <560000000>;
				opp-hz-real = /bits/ 64 <560000000>,
					      /bits/ 64 <560000000>;
				opp-microvolt = <700000>;
			};
			opp-800000000 {
				opp-hz = /bits/ 64 <800000000>;
				opp-hz-real = /bits/ 64 <800000000>,
					      /bits/ 64 <800000000>;
				opp-microvolt = <800000>;
			};
		};

		afe: audio-controller@11220000 {
			compatible = "mediatek,mt8365-afe-pcm";
			#sound-dai-cells = <0>;
			reg = <0 0x11220000 0 0x1000>,
			      <0 0x11221000 0 0xA000>;
			interrupts = <GIC_SPI 97 IRQ_TYPE_LEVEL_LOW>;
			power-domains = <&spm MT8365_POWER_DOMAIN_AUDIO>;
			clocks = <&topckgen CLK_TOP_AUDIO_SEL>,
				 <&topckgen CLK_TOP_AUD_I2S0_M>,
				 <&topckgen CLK_TOP_AUD_I2S1_M>,
				 <&topckgen CLK_TOP_AUD_I2S2_M>,
				 <&topckgen CLK_TOP_AUD_I2S3_M>,
				 <&topckgen CLK_TOP_AUD_TDMOUT_M>,
				 <&topckgen CLK_TOP_AUD_TDMOUT_B>,
				 <&topckgen CLK_TOP_AUD_TDMIN_M>,
				 <&topckgen CLK_TOP_AUD_TDMIN_B>,
				 <&topckgen CLK_TOP_AUD_SPDIF_M>,
				 <&topckgen CLK_TOP_AUD_SPDIF_SEL>,
				 <&topckgen CLK_TOP_AUD_ENGEN1_SEL>,
				 <&topckgen CLK_TOP_AUD_ENGEN2_SEL>,
				 <&topckgen CLK_TOP_AUD_1_SEL>,
				 <&topckgen CLK_TOP_AUD_2_SEL>,
				 <&topckgen CLK_TOP_APLL_I2S0_SEL>,
				 <&topckgen CLK_TOP_APLL_I2S1_SEL>,
				 <&topckgen CLK_TOP_APLL_I2S2_SEL>,
				 <&topckgen CLK_TOP_APLL_I2S3_SEL>,
				 <&topckgen CLK_TOP_APLL_TDMOUT_SEL>,
				 <&topckgen CLK_TOP_APLL_TDMIN_SEL>,
				 <&topckgen CLK_TOP_APLL_SPDIF_SEL>,
				 <&topckgen CLK_TOP_SYSPLL3_D4>,
				 <&topckgen CLK_TOP_CLK26M>,
				 <&topckgen CLK_TOP_SYSPLL1_D4>,
				 <&topckgen CLK_TOP_SYSPLL4_D2>,
				 <&topckgen CLK_TOP_AUD_INTBUS_SEL>;
			clock-names = "top_audio_sel",
				      "audio_i2s0_m",
				      "audio_i2s1_m",
				      "audio_i2s2_m",
				      "audio_i2s3_m",
				      "audio_tdmout_m",
				      "audio_tdmout_b",
				      "audio_tdmin_m",
				      "audio_tdmin_b",
				      "audio_spdif_m",
				      "spdif_in",
				      "engen1",
				      "engen2",
				      "aud1",
				      "aud2",
				      "i2s0_m_sel",
				      "i2s1_m_sel",
				      "i2s2_m_sel",
				      "i2s3_m_sel",
				      "tdmout_m_sel",
				      "tdmin_m_sel",
				      "spdif_b_sel",
				      "syspll3_d4",
				      "top_clk26m_clk",
				      "syspll1_d4",
				      "syspll4_d2",
				      "audio_intbus_sel";
			assigned-clocks = <&topckgen CLK_TOP_AUD_1_SEL>,
					  <&topckgen CLK_TOP_AUD_2_SEL>,
					  <&topckgen CLK_TOP_AUD_ENGEN1_SEL>,
					  <&topckgen CLK_TOP_AUD_ENGEN2_SEL>;
			assigned-clock-parents = <&topckgen CLK_TOP_APLL1>,
						 <&topckgen CLK_TOP_APLL2>,
						 <&topckgen CLK_TOP_APLL1_D8>,
						 <&topckgen CLK_TOP_APLL2_D8>;
			mediatek,topckgen-regmap = <&topckgen>;
			status = "disabled";
		};

		ethernet: ethernet@112a0000 {
			compatible = "mediatek,mt8365-eth";
			reg = <0 0x112a0000 0 0x1000>;
			mediatek,pericfg = <&infracfg>;
			interrupts = <GIC_SPI 25 IRQ_TYPE_LEVEL_HIGH>;
			clocks = <&topckgen CLK_TOP_ETH_SEL>,
				 <&infracfg CLK_IFR_NIC_AXI>,
				 <&infracfg CLK_IFR_NIC_SLV_AXI>;
			clock-names = "core", "reg", "trans";
			status = "disabled";
		};

		gce: gce@1023c000 {
			compatible = "mediatek,mt8365-gce",
						"mediatek,mt8173-gce";
			reg = <0 0x1023c000 0 0x4000>;
			interrupts = <GIC_SPI 98 IRQ_TYPE_LEVEL_LOW>,
				     <GIC_SPI 99 IRQ_TYPE_LEVEL_LOW>;
			clocks = <&infracfg CLK_IFR_GCE>,
					<&infracfg CLK_IFR_GCE_26M>;
			clock-names = "gce", "GCE_TIMER";

			#mbox-cells = <3>;
			#subsys-cells = <3>;
		};

		vcu: vcu@16000000 {
			compatible = "mediatek-vcu",
				     "mediatek,mt8183-vcu";
			mediatek,vcuid = <0>;
			mediatek,vcuname = "vcu";
			reg = <0 0x16000000 0 0x40000>,	    /* VDEC_BASE */
				 <0 0x17020000 0 0x10000>,  /* VENC_BASE */
				 <0 0x19002000 0 0x1000>;   /* VENC_LT */
			iommus = <&iommu M4U_PORT_HW_VDEC_MC_EXT>;
		};

		vcodec_dec: codec@16000000 {
			compatible = "mediatek,mt8365-vcodec-dec",
						"mediatek,mt8183-vcodec-dec", 
						"syscon";
			reg = <0 0x16000000 0 0x1000>,		/* VDEC_SYS */
			      <0 0x16025000 0 0x1000>,		/* VDEC_MISC */
			      <0 0x16020000 0 0x800>,		/* VDEC_VLD */
			      <0 0x16020800 0 0x800>,		/* VDEC_TOP */
			      <0 0x16021000 0 0x1000>,		/* VDEC_MC */
			      <0 0x16022000 0 0x1000>,		/* VDEC_AVC_VLD */
			      <0 0x16023000 0 0x1000>,		/* VDEC_AVC_MV */
			      <0 0x16024000 0 0x1000>,		/* VDEC_PP */
			      <0 0x16027800 0 0x800>,		/* VP8_VLD */
			      <0 0x16026000 0 0x800>,		/* VP6_VD */
			      <0 0x16026800 0 0x800>,		/* VP8_VLD2 */
			      <0 0x16028000 0 0x400>,		/* HEVC_VLD */
			      <0 0x16028400 0 0x400>,		/* VP9_VLD */
			      <0 0x16030000 0 0x1000>;		/* IMAGE_RESZ */
			mediatek,larb = <&larb3>;
			interrupts = <GIC_SPI 177 IRQ_TYPE_LEVEL_LOW>;
			iommus =
				<&iommu M4U_PORT_HW_VDEC_MC_EXT>,
				<&iommu M4U_PORT_HW_VDEC_PP_EXT>,
				<&iommu M4U_PORT_HW_VDEC_PRED_RD_EXT>,
				<&iommu M4U_PORT_HW_VDEC_PRED_WR_EXT>,
				<&iommu M4U_PORT_HW_VDEC_PPWRAP_EXT>,
				<&iommu M4U_PORT_HW_VDEC_TILE_EXT>,
				<&iommu M4U_PORT_HW_VDEC_VLD_EXT>,
				<&iommu M4U_PORT_HW_VDEC_VLD2_EXT>,
				<&iommu M4U_PORT_HW_VDEC_AVC_MV_EXT>,
				<&iommu M4U_PORT_HW_VDEC_RG_CTRL_DMA_EXT>;
			mediatek,vpu = <&vcu>;
			power-domains = <&spm MT8365_POWER_DOMAIN_VDEC>;
			clocks =
				<&vdecsys CLK_VDEC_VDEC>,
				<&vdecsys CLK_VDEC_LARB1>;
			clock-names =
				"vdec_sel",
				"normal";
			#clock-cells = <1>;
		};

		vcodec_enc: codec@17000000 {
			compatible = "mediatek,mt8365-vcodec-enc",
						"mediatek,mt8183-vcodec-enc";
			reg = <0 0x17020000 0 0x1000>,
				<0 0x17000000 0 0x1000>;
			mediatek,larb = <&larb1>;
			interrupts = <GIC_SPI 174 IRQ_TYPE_LEVEL_LOW>;
			iommus =
				<&iommu M4U_PORT_VENC_RCPU>,
				<&iommu M4U_PORT_VENC_REC>,
				<&iommu M4U_PORT_VENC_BSDMA>,
				<&iommu M4U_PORT_VENC_SV_COMV>,
				<&iommu M4U_PORT_VENC_RD_COMV>,
				<&iommu M4U_PORT_VENC_CUR_LUMA>,
				<&iommu M4U_PORT_VENC_CUR_CHROMA>,
				<&iommu M4U_PORT_VENC_REF_LUMA>,
				<&iommu M4U_PORT_VENC_REF_CHROMA>;
			mediatek,vpu = <&vcu>;
			power-domains = <&spm MT8365_POWER_DOMAIN_VENC>;
			clocks = <&vencsys CLK_VENC>;
			clock-names = "img_venc";
			#clock-cells = <1>;
		};

		camsv1: camsv@15050000 {
			compatible = "mediatek,mt8365-camsv";
			reg = <0 0x15050000 0 0x0040>,
			      <0 0x15050208 0 0x0020>,
			      <0 0x15050400 0 0x0100>;
			interrupts = <GIC_SPI 186 IRQ_TYPE_LEVEL_LOW>;
			clocks = <&camsys CLK_CAM>,
				 <&camsys CLK_CAMTG>,
				 <&camsys CLK_CAMSV0>;
			clock-names = "camsys_cam_cgpdn", "camsys_camtg_cgpdn",
						"camsys_camsv";
			iommus = <&iommu M4U_PORT_CAM_IMGO>;
			mediatek,larb = <&larb2>;
			power-domains = <&spm MT8365_POWER_DOMAIN_CAM>;
			status = "disabled";

			ports {
				#address-cells = <1>;
				#size-cells = <0>;
				port@0 {
					reg = <0>;
					camsv1_endpoint: endpoint {
						remote-endpoint =
							<&seninf_camsv1_endpoint>;
					};
				};
			};
		};

		camsv2: camsv@15050800 {
			compatible = "mediatek,mt8365-camsv";
			reg = <0 0x15050800 0 0x0040>,
			      <0 0x15050228 0 0x0020>,
			      <0 0x15050C00 0 0x0100>;
			interrupts = <GIC_SPI 187 IRQ_TYPE_LEVEL_LOW>;
			clocks = <&camsys CLK_CAM>,
				 <&camsys CLK_CAMTG>,
				 <&camsys CLK_CAMSV1>;
			clock-names = "camsys_cam_cgpdn", "camsys_camtg_cgpdn",
						"camsys_camsv";
			iommus = <&iommu M4U_PORT_CAM_IMGO>;

			mediatek,larb = <&larb2>;
			power-domains = <&spm MT8365_POWER_DOMAIN_CAM>;
			status = "disabled";

			ports {
				#address-cells = <1>;
				#size-cells = <0>;
				port@0 {
					reg = <0>;
					camsv2_endpoint: endpoint {
						remote-endpoint =
							<&seninf_camsv2_endpoint>;
					};
				};
			};
		};

		seninf: seninf@15040000 {
			compatible = "mediatek,mt8365-seninf";
			reg = <0 0x15040000 0 0x6000>;
			interrupts = <GIC_SPI 210 IRQ_TYPE_LEVEL_LOW>;
			clocks = <&camsys CLK_CAM_SENIF>,
				 <&topckgen CLK_TOP_SENIF_SEL>;
			clock-names = "cam_seninf", "top_mux_seninf";

			power-domains = <&spm MT8365_POWER_DOMAIN_CAM>;

			phys = <&mipi_rx 0>, <&mipi_rx 1>, <&mipi_rx 3>,
			       <&mipi_rx 4>;
			phy-names = "csi0", "csi1", "csi0a", "csi0b";

			status = "disabled";

			ports {
				#address-cells = <1>;
				#size-cells = <0>;

				port@0 {
					reg = <0>;
				};

				port@1 {
					reg = <1>;
				};

				port@2 {
					reg = <2>;
				};

				port@3 {
					reg = <3>;
				};

				port@4 {
					reg = <4>;
					seninf_camsv1_endpoint: endpoint {
						remote-endpoint =
							<&camsv1_endpoint>;
					};
				};

				port@5 {
					reg = <5>;
					seninf_camsv2_endpoint: endpoint {
						remote-endpoint =
							<&camsv2_endpoint>;
					};
				};
			};
		};

		mipi_rx: mipi-dphy@11c10000 {
			compatible = "mediatek,mt8365-mipi-dphy";
			reg = <0 0x11C10000 0 0x4000>;
			#phy-cells = <1>;
		};

		vpu0: vpu0@0x19100000 {
			compatible = "mediatek,mt8365-rproc-apu";
			reg = <0 0x19180000 0 0x94000>;
			reg-names = "mmio";
			interrupts = <GIC_SPI 199 IRQ_TYPE_LEVEL_LOW>;

			iommus = <&iommu M4U_PORT_APU_READ>,
				 <&iommu M4U_PORT_APU_WRITE>;

			clocks = <&apu CLK_APU_IPU_CK>,
				 <&apu CLK_APU_AXI>,
				 <&apu CLK_APU_JTAG>,
				 <&apu CLK_APU_IF_CK>,
				 <&apu CLK_APU_EDMA>,
				 <&apu CLK_APU_AHB>,
				 <&infracfg CLK_IFR_APU_AXI>,
				 <&mmsys CLK_MM_MM_SMI_CAM>;

			clock-names = "ipu",
				      "axi",
				      "jtag",
				      "if_ck",
				      "edma",
				      "ahb",
				      "ifr_apu_axi",
				      "smi_cam";

			power-domains = <&spm MT8365_POWER_DOMAIN_APU>;

			status = "disabled";
		 };
	};
};
